# ARMv8M-Extended register map
Registers are read-only, no defined reset value unless marked. A register's access mark holds for its fields unless they carry their own. Offsets are from the block's base; [hi:lo] are bit positions; {n}, {i} and the like mark numbered series.

## PMU_Ext — Performance Monitoring Unit Extension
Base 0xE0003000
{0x0+4i} Performance Monitoring Unit Event Counter Register[{i}] (i=0..7) rw — Holds performance counter, which count events
  [15:0] Counter — The counter counts whenever the selected event occurs, and either of the following conditions are met: SecureNoninvasiveDebugAllowed()==TRUE; The source of the event is Non-secure and NoninvasiveDebugAllowed()==TRUE.
0x7C PMU_CCNTR rw — Performance Monitoring Unit Cycle Counter Register holds the value of the cycle counter, which counts processor clock cycles
{0x400+4i} Performance Monitoring Unit Event Type and Filter Register[{i}] (i=0..7) rw — Configures the event counter
  [15:0] evtCount — The event number of the event that is counted by event counter PMU_EVCNTR0-7
0x47C PMU_CCFILTR rw — This register is RES0
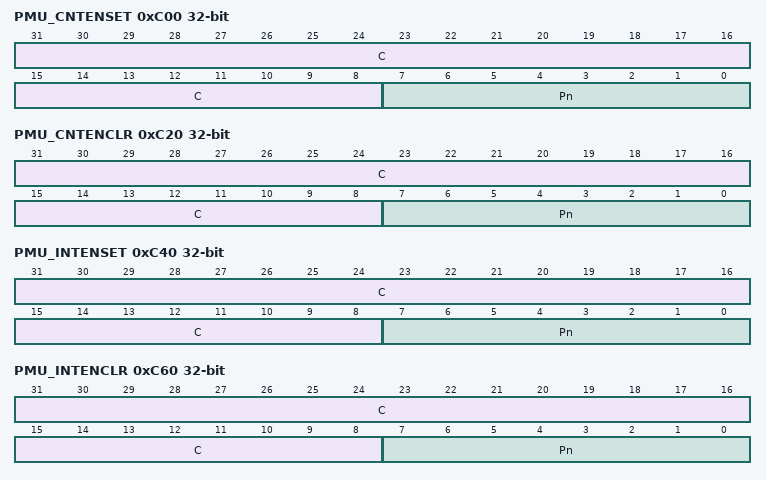
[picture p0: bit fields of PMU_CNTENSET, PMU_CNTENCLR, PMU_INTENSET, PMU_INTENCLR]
0xC00 PMU_CNTENSET rw — Performance Monitoring Unit Count Enable Set Register enables the PMU_CCNTR register and PMU_EVCNTR0-7 registers
  [31:8] C — PMU_CCNTR enable bit
  [7:0] Pn — Event counter PMU_EVCNTR0-7 enable bit
0xC20 PMU_CNTENCLR rw — Performance Monitoring Unit Count Enable Clear Register disables the PMU_CCNTR register and PMU_EVCNTR0-7 registers
  [31:8] C — PMU_CCNTR disable bit
  [7:0] Pn — Event counter PMU_EVCNTR0-7 enable bit
0xC40 PMU_INTENSET rw — Performance Monitoring Unit Interrupt Enable Set Register enables the generation of interrupt requests on overflows from the PMU_CCNTR, and the event counter, PMU_EVCNTR.
  [31:8] C — PMU_CCNTR interrupt request enable bit
  [7:0] Pn — Event counter overflow interrupt request disable bit for PMU_EVCNTR0-7
0xC60 PMU_INTENCLR rw — Performance Monitoring Unit Interrupt Enable Clear Register disables the generation of interrupt requests on overflows from the PMU_CCNTR, and the event counters, PMU_EVCNTR
  [31:8] C — PMU_CCNTR overflow interrupt request disable bit
  [7:0] Pn — Event counter overflow interrupt request enable bit for PMU_EVCNTRn. Enable the overflow interrupt for PMU_EVCNTR0-7
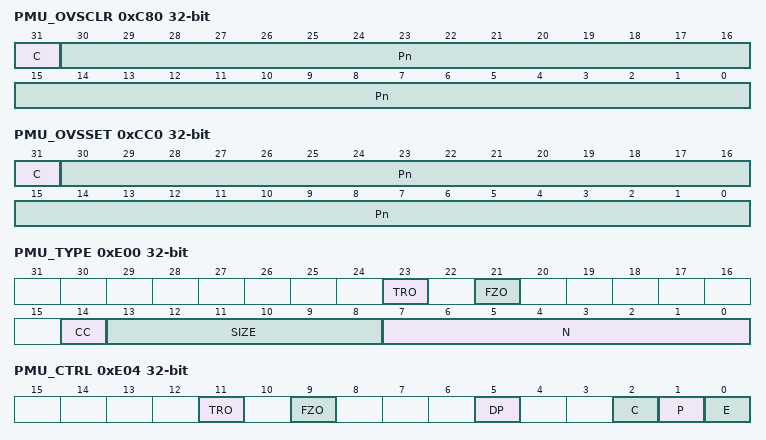
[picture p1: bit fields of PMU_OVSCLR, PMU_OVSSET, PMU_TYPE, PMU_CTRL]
0xC80 PMU_OVSCLR rw — Performance Monitoring Unit Overflow Flag Status Clear Register contains the state of the overflow bit for the PMU_CCNTR, and each of the implemented event counters, PMU_EVCNTRn. Writing to this register clears these bits.
  [31] C — PMU_CCNTR overflow bit. Clears the PMU_CCNTR overflow bit.
  [30:0] Pn — Event counter overflow clear bit for PMU_EVCNTRn. Clears the PMU_EVCNTRn overflow bit
0xCA0 PMU_SWINC wo — Performance Monitoring Unit Software Increment Register increments a counter that is configured to count the software increment event, event 0x00
  [7:0] Pn — Event counter software increment bit for PMU_EVCNTRn. An event counter n, configured for SW_INCR events, increments on every write to bit n of this field.
0xCC0 PMU_OVSSET rw — Performance Monitoring Unit Overflow Flag Status Set Register performance Monitoring Unit Overflow Flag Status Set Register
  [31] C — PMU_CCNTR overflow bit. Sets the overflow status for PMU_CCNTR.
  [30:0] Pn — Event counter overflow set bit for PMU_EVCNTRn. Sets the overflow status for PMU_EVCNTRn.
0xE00 PMU_TYPE — Performance Monitoring Unit Type Register contains information regarding what the PMU supports
  [23] TRO — Trace-on-overflow not supported. This bit is 0b0.
  [21] FZO — Freeze-on-overflow is supported. This bit is 0b1.
  [14] CC — A dedicated cycle counter is present. This bit is 0b1.
  [13:8] SIZE — Size of counters. This field determines the spacing of counters in the memory-map. This field is 0b011111.
  [7:0] N — Number of counters implemented in addition to the cycle counter, PMU_CCNTR. This field is set to 0b00001000, indicating that 8 16-bit event counters are present in addition to PMU_CCNTR.
0xE04 PMU_CTRL rw — Performance Monitoring Unit Control Register configures and controls the PMU
  [11] TRO — Trace-on-overflow not supported in Cortex-M55. Therefore, this bit is 0b0.
  [9] FZO — Freeze-on-overflow. Stops events being counted once PMU_OVSCLR or PMU_OVSSET is non-zero.
    0=No effect; 1=While PMU_OVSCLR or PMU_OVSSET is non-zero, event counters do not count events
  [5] DP — Disable cycle counter when event counting is prohibited
  [2] C — Cycle counter reset. Reset the PMU_CCNTR counter.
    0=No action; 1=Reset PMU_CCNTR to zero
  [1] P — Event counter reset
    0=No action; 1=Reset all event counters, except PMU_CCNTR, to zero
  [0] E — Enable. Enable the event counters.
    0=All counters, including PMU_CCNTR, are disabled; 1=PMU_CNTENSET enable all counters
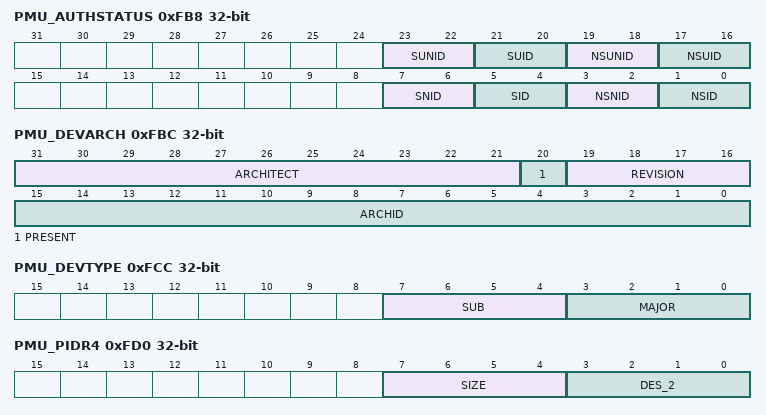
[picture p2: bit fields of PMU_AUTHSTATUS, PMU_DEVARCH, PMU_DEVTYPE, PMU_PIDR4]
0xFB8 PMU_AUTHSTATUS — Performance Monitoring Unit Authentication Status Register provides information about the state of the implementation defined authentication interface for the PMU
  [23:22] SUNID — Secure Unprivileged Non-invasive Debug Allowed. Indicates that Unprivileged Non-invasive Debug is allowed for the Secure state.
    0=Unprivileged Non-invasive debug not implemented; 2=Secure Non-invasive debug prohibited; 3=Secure Non-invasive debug allowed in unprivileged mode
  [21:20] SUID — Secure Unprivileged Invasive Debug Allowed. Indicates that Unprivileged Invasive Debug is allowed for the Secure state.
    0=Unprivileged Invasive debug not implemented; 2=Secure Invasive debug prohibited; 3=Secure Invasive debug allowed in unprivileged mode
  [19:18] NSUNID — Non-secure Unprivileged Non-invasive Debug Allowed. Indicates that Unprivileged Non-invasive Debug is allowed for the Non-secure state.
    0=Unprivileged Non-invasive debug not implemented; 2=Non-secure Non-invasive debug prohibited; 3=Non-secure Non-invasive debug allowed in unprivileged mode
  [17:16] NSUID — Non-secure Unprivileged Invasive Debug Allowed. Indicates that Unprivileged Halting Debug is allowed for the Non-secure state.
    0=Unprivileged halting debug not implemented; 2=Non-secure halting debug prohibited; 3=Non-secure halting debug allowed in unprivileged mode
  [7:6] SNID — Secure Non-invasive Debug. Indicates whether Secure Non-invasive debug is implemented and allowed.
    0=Security Extension not implemented; 2=Security Extension implemented and Secure Non-invasive debug not allowed; 3=Security Extension implemented and Secure Non-invasive debug allowed
  [5:4] SID — Secure Invasive Debug. Indicates whether Secure invasive debug is implemented and allowed.
    0=Security Extension not implemented; 2=Security Extension implemented and Secure invasive debug not allowed; 3=Security Extension implemented and Secure invasive debug allowed
  [3:2] NSNID — Non-secure Non-invasive Debug. Indicates whether Non-secure Non-invasive debug is allowed.
    2=Non-secure Non-invasive debug not allowed; 3=Non-secure Non-invasive debug allowed
  [1:0] NSID — Non-secure Invasive Debug. Indicates whether Non-secure invasive debug is allowed.
    2=Non-secure invasive debug not allowed; 3=Non-secure invasive debug allowed
0xFBC PMU_DEVARCH — Performance Monitoring Unit Device Architecture Register identifies the programmers model architecture of the PMU
  [31:21] ARCHITECT — Defines the architecture of the component. For the PMU, it is Arm Limited. Bits[31:28] are the JEP 106 continuation code, 0x4, and bits [27:21] are the JEP 106 ID code, 0x3B.
  [20] PRESENT — Determines the presence of DEVARCH. When set to 1, indicates that the DEVARCH is present. This bit reads as 0x1.
  [19:16] REVISION — Defines the architecture revision. For the PMU, the revision defined by Armv8.1‑M is 0x2.
  [15:0] ARCHID — Defines this part to be an Armv8‑M debug component. For the PMU, bits [15:12] are 0x0, bits [11:0] are 0xA06.
0xFCC PMU_DEVTYPE — Performance Monitoring Unit Device Type Register indicates to a debugger that the PMU is a part of the processor interface
  [7:4] SUB — Subtype. This field reads as 0x1.
  [3:0] MAJOR — Major type. This field reads as 0x6.
0xFD0 PMU_PIDR4 — Performance Monitoring Unit Peripheral Identification Register 4 provides information to identify the PMU.
  [7:4] SIZE — Size of the component. This field is RAZ.
  [3:0] DES_2 — Designer, JEP 106 continuation code, least significant nibble. For Arm Limited, this field is 0x4.
0xFE0 PMU_PIDR0 — Performance Monitoring Unit Peripheral Identification Register 0 provides information to identify the PMU
  [7:4] PART_0 — Part number, least significant byte. This field reads 0x22.
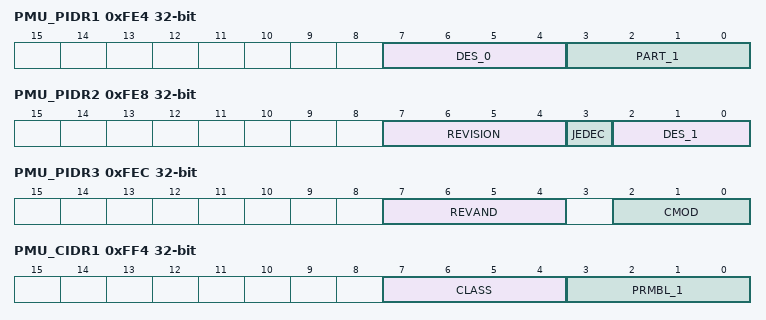
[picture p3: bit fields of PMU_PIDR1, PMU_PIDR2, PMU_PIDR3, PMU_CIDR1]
0xFE4 PMU_PIDR1 — Performance Monitoring Unit Peripheral Identification Register 1 provides information to identify the PMU
  [7:4] DES_0 — Designer, least significant nibble of JEP 106 ID code. For Arm Limited, this field 0xB.
  [3:0] PART_1 — Part number, most significant nibble. This field is 0xD.
0xFE8 PMU_PIDR2 — Performance Monitoring Unit Peripheral Identification Register 2 provides information to identify the PMU.
  [7:4] REVISION — Part major revision. Parts can also use this field to extend Part number to 16-bits. This field reads as 0x0000.
  [3] JEDEC — Indicates a JEP10 identity code. This is RAO.
  [2:0] DES_1 — Designer, most significant bits of JEP 106 ID code. For Arm Limited, this field reas as 0b011.
0xFEC PMU_PIDR3 — Performance Monitoring Unit Peripheral Identification Register 3 provides information to identify the PMU
  [7:4] REVAND — Part minor revision. This field is 0x0000.
  [2:0] CMOD — Customer modified. This field is 0x0000.
0xFF0 PMU_CIDR0 — Performance Monitoring Unit Component Identification Register 0 provides information to identify a PMU component
  [7:0] PRMBL_0 — Preamble. This field reads 0x0D.
0xFF4 PMU_CIDR1 — Performance Monitoring Unit Component Identification Register 1 provides information to identify a PMU component
  [7:4] CLASS — Component class. This field reads 0x0.
  [3:0] PRMBL_1 — Preamble. This field reads 0x0.
0xFF8 PMU_CIDR2 — Performance Monitoring Unit Component Identification Register 2 provides information to identify a PMU component
  [3:0] PRMBL_2 — Preamble. This field reads 0x05.
0xFFC PMU_CIDR3 — Performance Monitoring Unit Component Identification Register 3 provides information to identify a PMU component
  [3:0] PRMBL_3 — Preamble. This field reads 0xB1.
